# TLE987x register map
Vendor: Infineon; Series: MOTIX MCU; File version: 4.2
CPU: CM3 r0p0, little endian, no MPU, no FPU, 4 interrupt priority bits
Registers are 32-bit, read-write, reset 0x0 unless marked. A register's access mark holds for its fields unless they carry their own. Offsets are from the block's base; [hi:lo] are bit positions; {n}, {i} and the like mark numbered series; 'fields as' and 'values as' point back to an identical list.

## CPU — CPU Core
Base 0xE000E000
0x04 ICT ro — Interrupt Controller Type
  [4:0] INTLINESNUM — Interrupt Lines
    0=0 to 32; 1=33 to 64; 2=65 to 95; 3=97 to 128; 4=129 to 160; 5=161 to 192; 6=193 to 224; 7=225 to 256
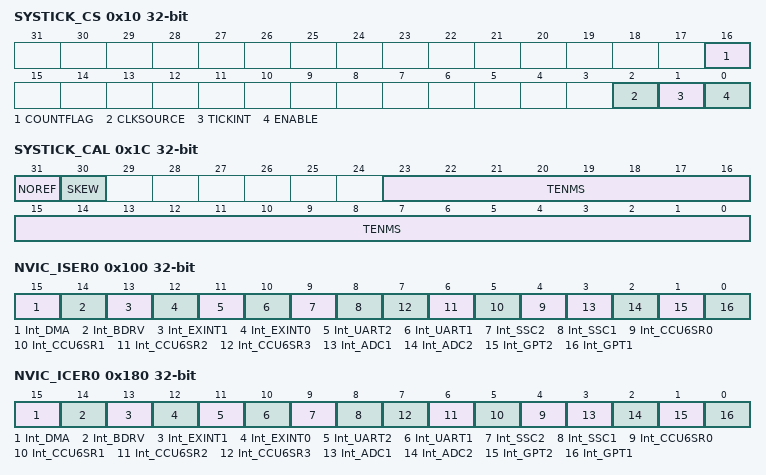
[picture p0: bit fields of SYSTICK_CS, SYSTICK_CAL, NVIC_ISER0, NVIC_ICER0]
0x10 SYSTICK_CS — SysTick Control and Status
  [16] COUNTFLAG
  [2] CLKSOURCE
    0=external reference clock (STCLK : 4:1 from hclk); 1=core clock (HCLK)
  [1] TICKINT — Enables SysTick exception request
    0=DISABLED (counting down to zero does not assert the SysTick exception request); 1=ENABLED (counting down to zero asserts the SysTick exception request)
  [0] ENABLE
    0=counter disabled; 1=counter operates in a multi-shot way. That is, counter loads with the Reload value and then begins counting down. On reaching 0, it sets the COUNTFLAG to 1 and optionally pends the SysTick handler, based on TICKINT. It then loads the Reload value again, and begins counting.
0x14 SYSTICK_RL (reset mask 0xFF000000) — SysTick Reload Value
  [23:0] RELOAD
0x18 SYSTICK_CUR (reset mask 0xFF000000) — SysTick Current Value
  [23:0] CURRENT
0x1C SYSTICK_CAL ro (reset mask 0x3F000000) — SysTick Calibration Value
  [31] NOREF — No Reference Clock
    0=n.u; 1=the reference clock is not provided
  [30] SKEW
    0=n.u; 1=the calibration value is not exactly 10 ms because of clock frequency. This could affect its suitability as a software real time clock.
  [23:0] TENMS
0x100 NVIC_ISER0 — Interrupt Set-Enable
  [all] fields
    0=DISABLE (disables interrupt for read operation, no effect for write operation); 1=ENABLE (enables interrupt for read and write operation)
  [15] Int_DMA — Interrupt Set for DMA
  [14] Int_BDRV — Interrupt Set for Bridge Driver
  [13] Int_EXINT1 — Interrupt Set for External Int 1
  [12] Int_EXINT0 — Interrupt Set for External Int 0
  [11] Int_UART2 — Interrupt Set for UART2
  [10] Int_UART1 — Interrupt Set for UART1
  [9] Int_SSC2 — Interrupt Set for SSC2
  [8] Int_SSC1 — Interrupt Set for SSC1
  [n+4] Int_CCU6SR{n} (n=0..3) — Interrupt Set for CCU6 SR{n}
  [3] Int_ADC1 — Interrupt Set for ADC1
  [2] Int_ADC2 — Interrupt Set for MU, ADC2
  [1] Int_GPT2 — Interrupt Set for GPT2
  [0] Int_GPT1 — Interrupt Set for GPT1
0x180 NVIC_ICER0 — Interrupt Clear-Enable
  [all] fields
    values as the fields of NVIC_ISER0
  [15] Int_DMA — Interrupt Clr for DMA
  [14] Int_BDRV — Interrupt Clear for Bridge Driver
  [13] Int_EXINT1 — Interrupt Clear for External Int 1
  [12] Int_EXINT0 — Interrupt Clear for External Int 0
  [11] Int_UART2 — Interrupt Clear for UART2
  [10] Int_UART1 — Interrupt Clear for UART1
  [9] Int_SSC2 — Interrupt Clear for SSC2
  [8] Int_SSC1 — Interrupt Clear for SSC1
  [n+4] Int_CCU6SR{n} (n=0..3) — Interrupt Clear for CCU6 SR{n}
  [3] Int_ADC1 — Interrupt Clear for ADC1
  [2] Int_ADC2 — Interrupt Clear for MU, ADC2
  [1] Int_GPT2 — Interrupt Clear for GPT2
  [0] Int_GPT1 — Interrupt Clear for GPT1
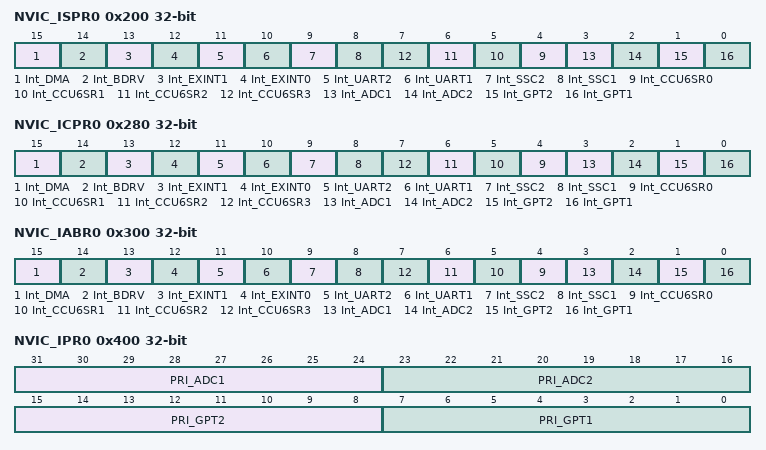
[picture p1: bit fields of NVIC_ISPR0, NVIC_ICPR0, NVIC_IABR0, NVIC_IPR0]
0x200 NVIC_ISPR0 — Interrupt Set-Pending
  [all] fields
    values as the fields of NVIC_ISER0
  [15] Int_DMA — Interrupt Set Pend for DMA
  [14] Int_BDRV — Interrupt Set Pending for Bridge Driver
  [13] Int_EXINT1 — Interrupt Set Pending for External Int 1
  [12] Int_EXINT0 — Interrupt Set Pending for External Int 0
  [11] Int_UART2 — Interrupt Set Pending for UART2
  [10] Int_UART1 — Interrupt Set Pending for UART1
  [9] Int_SSC2 — Interrupt Set Pending for SSC2
  [8] Int_SSC1 — Interrupt Set Pending for SSC1
  [n+4] Int_CCU6SR{n} (n=0..3) — Interrupt Set Pending for CCU6 SR{n}
  [3] Int_ADC1 — Interrupt Set Pending for ADC1
  [2] Int_ADC2 — Interrupt Set Pending for MU, ADC2
  [1] Int_GPT2 — Interrupt Set Pending for GPT2
  [0] Int_GPT1 — Interrupt Set Pending for GPT1
0x280 NVIC_ICPR0 — Interrupt Clear-Pending
  [all] fields
    values as the fields of NVIC_ISER0
  [15] Int_DMA — Interrupt Clr Pend for DMA
  [14] Int_BDRV — Interrupt Clear Pending for Bridge Driver
  [13] Int_EXINT1 — Interrupt Clear Pending for External Int 1
  [12] Int_EXINT0 — Interrupt Clear Pending for External Int 0
  [11] Int_UART2 — Interrupt Clear Pending for UART2
  [10] Int_UART1 — Interrupt Clear Pending for UART1
  [9] Int_SSC2 — Interrupt Clear Pending for SSC2
  [8] Int_SSC1 — Interrupt Clear Pending for SSC1
  [n+4] Int_CCU6SR{n} (n=0..3) — Interrupt Clear Pending for CCU6 SR{n}
  [3] Int_ADC1 — Interrupt Clear Pending for ADC1
  [2] Int_ADC2 — Interrupt Clear Pending for MU, ADC2
  [1] Int_GPT2 — Interrupt Clear Pending for GPT2
  [0] Int_GPT1 — Interrupt Clear Pending for GPT1
0x300 NVIC_IABR0 ro — Active Bit Register Interrupt Active Flags
  [all] fields
    values as the fields of NVIC_ISER0
  [15] Int_DMA — Interrupt Active for DMA
  [14] Int_BDRV — Interrupt Active for Bridge Driver
  [13] Int_EXINT1 — Interrupt Active for External Int 1
  [12] Int_EXINT0 — Interrupt Active for External Int 0
  [11] Int_UART2 — Interrupt Active for UART2
  [10] Int_UART1 — Interrupt Active for UART1
  [9] Int_SSC2 — Interrupt Active for SSC2
  [8] Int_SSC1 — Interrupt Active for SSC1
  [n+4] Int_CCU6SR{n} (n=0..3) — Interrupt Active for CCU6 SR{n}
  [3] Int_ADC1 — Interrupt Active for ADC1
  [2] Int_ADC2 — Interrupt Active for MU, ADC2
  [1] Int_GPT2 — Interrupt Active for GPT2
  [0] Int_GPT1 — Interrupt Active for GPT1
0x400 NVIC_IPR0 — Interrupt Priority
  [31:24] PRI_ADC1 — Priority for ADC1
  [23:16] PRI_ADC2 — Priority for MU, ADC2
  [15:8] PRI_GPT2 — Priority for GPT2
  [7:0] PRI_GPT1 — Priority for GPT1
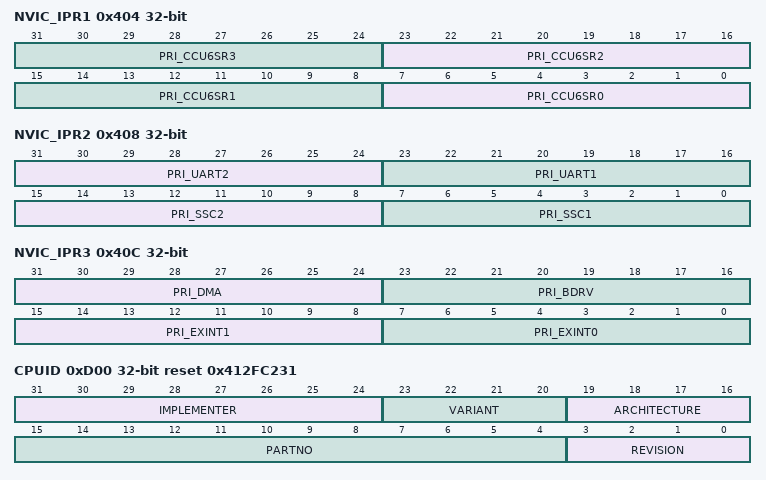
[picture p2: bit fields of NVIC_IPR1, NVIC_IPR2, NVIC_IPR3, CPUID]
0x404 NVIC_IPR1 — Interrupt Priority
  [8n+7:8n] PRI_CCU6SR{n} (n=0..3) — Priority for CCU6 SR{n}
0x408 NVIC_IPR2 — Interrupt Priority
  [31:24] PRI_UART2 — Priority for UART2
  [23:16] PRI_UART1 — Priority for UART1
  [15:8] PRI_SSC2 — Priority for SSC2
  [7:0] PRI_SSC1 — Priority for SSC1
0x40C NVIC_IPR3 — Interrupt Priority
  [31:24] PRI_DMA — Priority for DMA
  [23:16] PRI_BDRV — Priority for Bridge Driver
  [15:8] PRI_EXINT1 — Priority for Ext. Int 1
  [7:0] PRI_EXINT0 — Priority for Ext. Int 0
0xD00 CPUID ro reset 0x412FC231 — CPU ID Base Register
  [31:24] IMPLEMENTER — Implementer Code
  [23:20] VARIANT — Variant Number
  [19:16] ARCHITECTURE
  [15:4] PARTNO — Part Number
  [3:0] REVISION — Revision Number
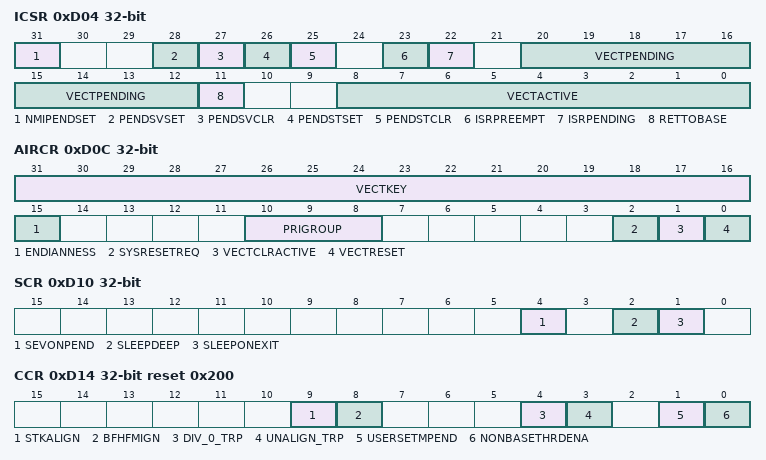
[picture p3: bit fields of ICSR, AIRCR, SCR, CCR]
0xD04 ICSR access per field — Interrupt Control State Register
  [31] NMIPENDSET rw
    0=on writes, has no effect. On reads, NMI is active.; 1=on writes, make the NMI exception active. On reads, NMI is active.
  [28] PENDSVSET rw — PendSV set-pending bit
    0=on writes, has no effect. On reads, PendSV is not pending.; 1=on writes, make PendSV exception pending. On reads, PendSV is pending.
  [27] PENDSVCLR wo — PendSV clear-pending bit
    0=no effect; 1=remove pending status
  [26] PENDSTSET rw — SysTick exception set-pending bit
    0=on writes, has no effect. On reads, SysTick is not pending.; 1=on writes, make SysTick exception pending. On reads, SysTick is pending.
  [25] PENDSTCLR wo — SysTick exception clear-pending bit
    0=no effect; 1=remove pending status
  [23] ISRPREEMPT ro
    0=will not service; 1=will service a pending exception
  [22] ISRPENDING ro — Interrupt pending flag. Excludes NMI and Faults
    0=no external interrupt is pending; 1=external interrupt is pending
  [20:12] VECTPENDING ro — Pending ISR number field
  [11] RETTOBASE ro
    0=There is an active exception other than the exception shown by IPSR; 1=There is no active exception other than any exception shown by IPSR
  [8:0] VECTACTIVE ro — Active ISR number field
0xD08 VTOR — Vector Table Offset Register
  [31:7] TBLOFF — Vector Table Offset
0xD0C AIRCR access per field — Application Interrupt/Reset Control Register
  [31:16] VECTKEY rw — Vector Key
  [15] ENDIANNESS ro — Memory System Endianness
    0=little endian; 1=big endian
  [10:8] PRIGROUP rw — Priority Grouping
  [2] SYSRESETREQ rw — System Reset Request
    0=do not request a reset; 1=request a reset
  [1] VECTCLRACTIVE rw — VECTCLRACTIVE for debug only
  [0] VECTRESET rw — VECTRESET for debug only
0xD10 SCR — System Control Register
  [4] SEVONPEND
    0=transitions from inactive to pending are not wake-up events; 1=transitions from inactive to pending are wake-up events
  [2] SLEEPDEEP
    0=selected sleep state is not deep sleep; 1=selected sleep state is deep sleep
  [1] SLEEPONEXIT
    0=do not enter sleep state; 1=enter sleep state
0xD14 CCR reset 0x200 — Configuration Control Register
  [9] STKALIGN — stack alignment
    0=guaranteed SP alignment is 4-byte, no SP adjustment is performed; 1=8-byte alignment guaranteed, SP adjusted if necessary
  [8] BFHFMIGN — Enables handlers with priority -1 or -2 to ignore data BusFaults caused by load and store instructions
    0=precise data access fault causes a lockup; 1=handler ignores the fault
  [4] DIV_0_TRP — Enables faulting or halting when the processor executes an SDIV or UDIV instruction with a divisor of 0
    0=trapping disabled; 1=trapping enabled
  [3] UNALIGN_TRP — Enables unaligned access traps
    0=trapping disabled; 1=trapping enabled
  [1] USERSETMPEND — Enables unprivileged software access to the STIR
    0=unprivileged software cannot access the STIR; 1=unprivileged software can access the STIR
  [0] NONBASETHRDENA — Indicates how the processor enters Thread mode
    0=any attempt to enter Thread mode at an execution priority level of other than base level faults; 1=the processor can enter Thread mode at any execution priority level because of a controlled return value
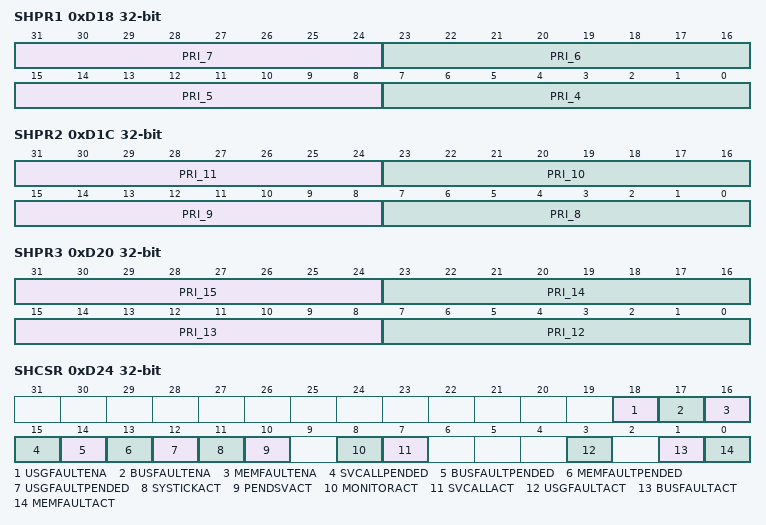
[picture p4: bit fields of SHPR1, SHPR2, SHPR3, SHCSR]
0xD18 SHPR1 — System Handler Priority Register 1
  [31:24] PRI_7 — Reserved for Priority of System Handler 7
  [23:16] PRI_6 — Priority of System Handler 6, UsageFault
  [15:8] PRI_5 — Priority of System Handler 5, BusFault
  [7:0] PRI_4 — Priority of System Handler 4, MemManage
0xD1C SHPR2 — System Handler Priority Register 2
  [31:24] PRI_11 — Priority of System Handler 11, SVCall
  [23:16] PRI_10 — Reserved for Priority of System Handler 10
  [15:8] PRI_9 — Reserved for Priority of System Handler 9
  [7:0] PRI_8 — Reserved for Priority of System Handler 8
0xD20 SHPR3 — System Handler Priority Register 3
  [31:24] PRI_15 — Priority of System Handler 15, SysTick
  [23:16] PRI_14 — Priority of System Handler 14, PendSV
  [15:8] PRI_13 — Reserved for Priority of System Handler 13
  [7:0] PRI_12 — Priority of System Handler 12, DebugMonitor
0xD24 SHCSR — System Handler Control and State Register
  [18] USGFAULTENA
    0=Disable UsageFault; 1=Enable UsageFault
  [17] BUSFAULTENA
    0=Disable BusFault; 1=Enable BusFault
  [16] MEMFAULTENA
    0=Disable MemManage fault; 1=Enable MemManage fault
  [15] SVCALLPENDED
    0=SVCall is not pending; 1=SVCall is pending
  [14] BUSFAULTPENDED
    0=BusFault is not pending; 1=BusFault is pending
  [13] MEMFAULTPENDED
    0=MemManage is not pending; 1=MemManage is pending
  [12] USGFAULTPENDED
    0=UsageFault is not pending; 1=UsageFault is pending
  [11] SYSTICKACT
    0=SysTick is not active; 1=SysTick is active
  [10] PENDSVACT
    0=PendSV is not active; 1=PendSV is active
  [8] MONITORACT
    0=Monitor is not active; 1=Monitor is active
  [7] SVCALLACT
    0=SVCall is not active; 1=SVCall is active
  [3] USGFAULTACT
    0=UsageFault is not active; 1=UsageFault is active
  [1] BUSFAULTACT
    0=BusFault is not active; 1=BusFault is active
  [0] MEMFAULTACT
    0=MemManage is not active; 1=MemManage is active
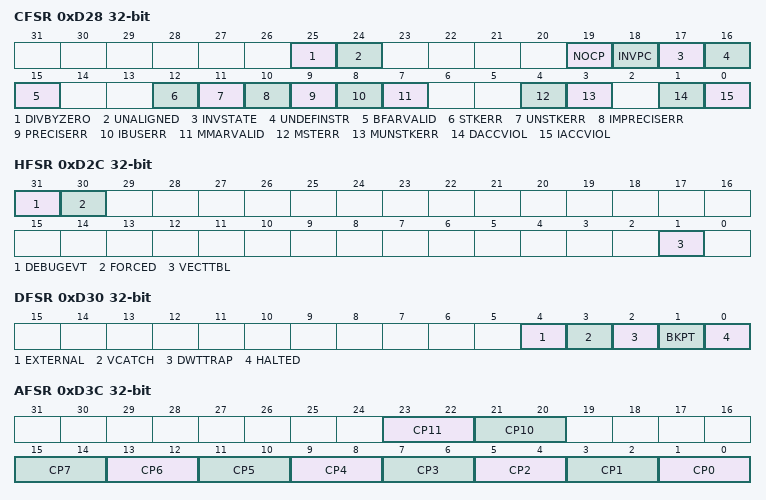
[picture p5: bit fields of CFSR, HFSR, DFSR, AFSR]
0xD28 CFSR — Configurable Fault Status Register
  [25] DIVBYZERO — Divide by Zero
    0=No Divide by zero error has occurred; 1=A divide by zero error has occurred
  [24] UNALIGNED — Unaligned access UsageFault
    0=No unaligned access error has occurred; 1=A unaligned access error has occurred
  [19] NOCP — No coprocessor UsageFault
    0=No coprocessor access error has occurred; 1=A coprocessor access error has occurred
  [18] INVPC — Invalid PC load UsageFault
    0=No integrity check error has occurred; 1=A integrity check error has occurred
  [17] INVSTATE — Invalid state UsageFault
    0=EPSR.T bit and EPSR.IT bits are valid for instruction execution; 1=Instruction executed with invalid EPSR.T or EPSR.IT field
  [16] UNDEFINSTR — Undefined instruction UsageFault
    0=No Undefined Instruction Usage fault has occurred; 1=The processor hat attempted to execute an undefined instruction. This might be an undefined instruction associated with an enabled coprocessor.
  [15] BFARVALID
    0=BFAR does not have valid contents; 1=BFAR has valid contents
  [12] STKERR — BusFault on stacking for exception entry
    0=No derived bus fault occurred; 1=A derived bus fault occurred on exception entry
  [11] UNSTKERR — BusFault on unstacking for a return from exception
    0=No derived bus fault occurred; 1=A derived bus fault occurred on exception return
  [10] IMPRECISERR — Imprecise data bus error
    0=No precise data access error has occurred; 1=An imprecise data access error has occurred
  [9] PRECISERR — Precise data bus error
    0=No precise data access error has occurred; 1=An imprecise data access error has occurred, and the processor has written the faulting address to the BFAR
  [8] IBUSERR — Instruction bus error
    0=No bus fault on an instruction prefetch has occurred; 1=A bus fault on an instruction prefetch has occurred. The fault is signalled only if the instruction is issued.
  [7] MMARVALID — MemManage Fault Address Register (MMFAR) valid flag
    0=MMAR does not have valid contents; 1=MMAR has valid contents
  [4] MSTERR — MemManage fault on stacking for exception entry
    0=No derived MemManage fault occurred; 1=A derived MemManage fault occurred on exception entry
  [3] MUNSTKERR — MemManage fault on unstacking for a return from exception
    0=No derived MemManage fault occurred; 1=A derived MemManage fault occurred on exception return
  [1] DACCVIOL — Data access violation flag
    0=No data access violation has occurred; 1=Data access violation. The MMAR shows the data address that the load or store tried to access.
  [0] IACCVIOL — Instruction access violation flag
    0=No MPU or Execute Never (XN) default memory map access violation has occurred; 1=MPU or Execute Never (XN) default memory map access violation on an instruction fetch has occurred. The fault is signalled only if the instruction is issued.
0xD2C HFSR — Hard Fault Status Register
  [31] DEBUGEVT — Debug Event
    0=No Debug event has occurred; 1=Debug event has occurred. The Debug Fault Status Register has been updated.
  [30] FORCED
    0=No priority escalation has occurred; 1=Processor has escalated a configurable priority exception to HardFault
  [1] VECTTBL
    0=No vector table read fault has occurred; 1=Vector table read fault has occurred
0xD30 DFSR — Debug Fault Status Register
  [4] EXTERNAL
    0=No EDBGRQ debug event; 1=EDBGRQ debug event
  [3] VCATCH — Vector Catch
    0=No vector catch triggered; 1=Vector catch triggered
  [2] DWTTRAP
    0=No current debug event generated by the DWT; 1=At least one current debug event generated by the DWT
  [1] BKPT
    0=No current breakpoint debug event; 1=At least one current breakpoint debug event
  [0] HALTED
    0=No active halt request debug event; 1=Halt request debug event active
0xD34 MMFAR reset not defined — MemManage Fault Status Register
  [31:0] ADDRESS — Data Address for an MPU Fault
0xD38 BFAR reset not defined — Bus Fault Status Register
  [31:0] ADDRESS — Data Address for a precise BusFault
0xD3C AFSR — Auxiliary Fault Status Register
  [all] fields
    0=Access denied. Any attempted access generates a NOCP UsageFault; 1=Privileged access only. An unprivileged access generates a NOCP UsageFault; 3=Full access
  [23:22] CP11 — Access Privileges for Coprocessor 11 (n= 0-7, 10, 11)
  [21:20] CP10 — Access Privileges for Coprocessor 10 (n= 0-7, 10, 11)
  [2n+1:2n] CP{n} (n=0..7) — Access Privileges for Coprocessor {n} (n= 0-7, 10, 11)
